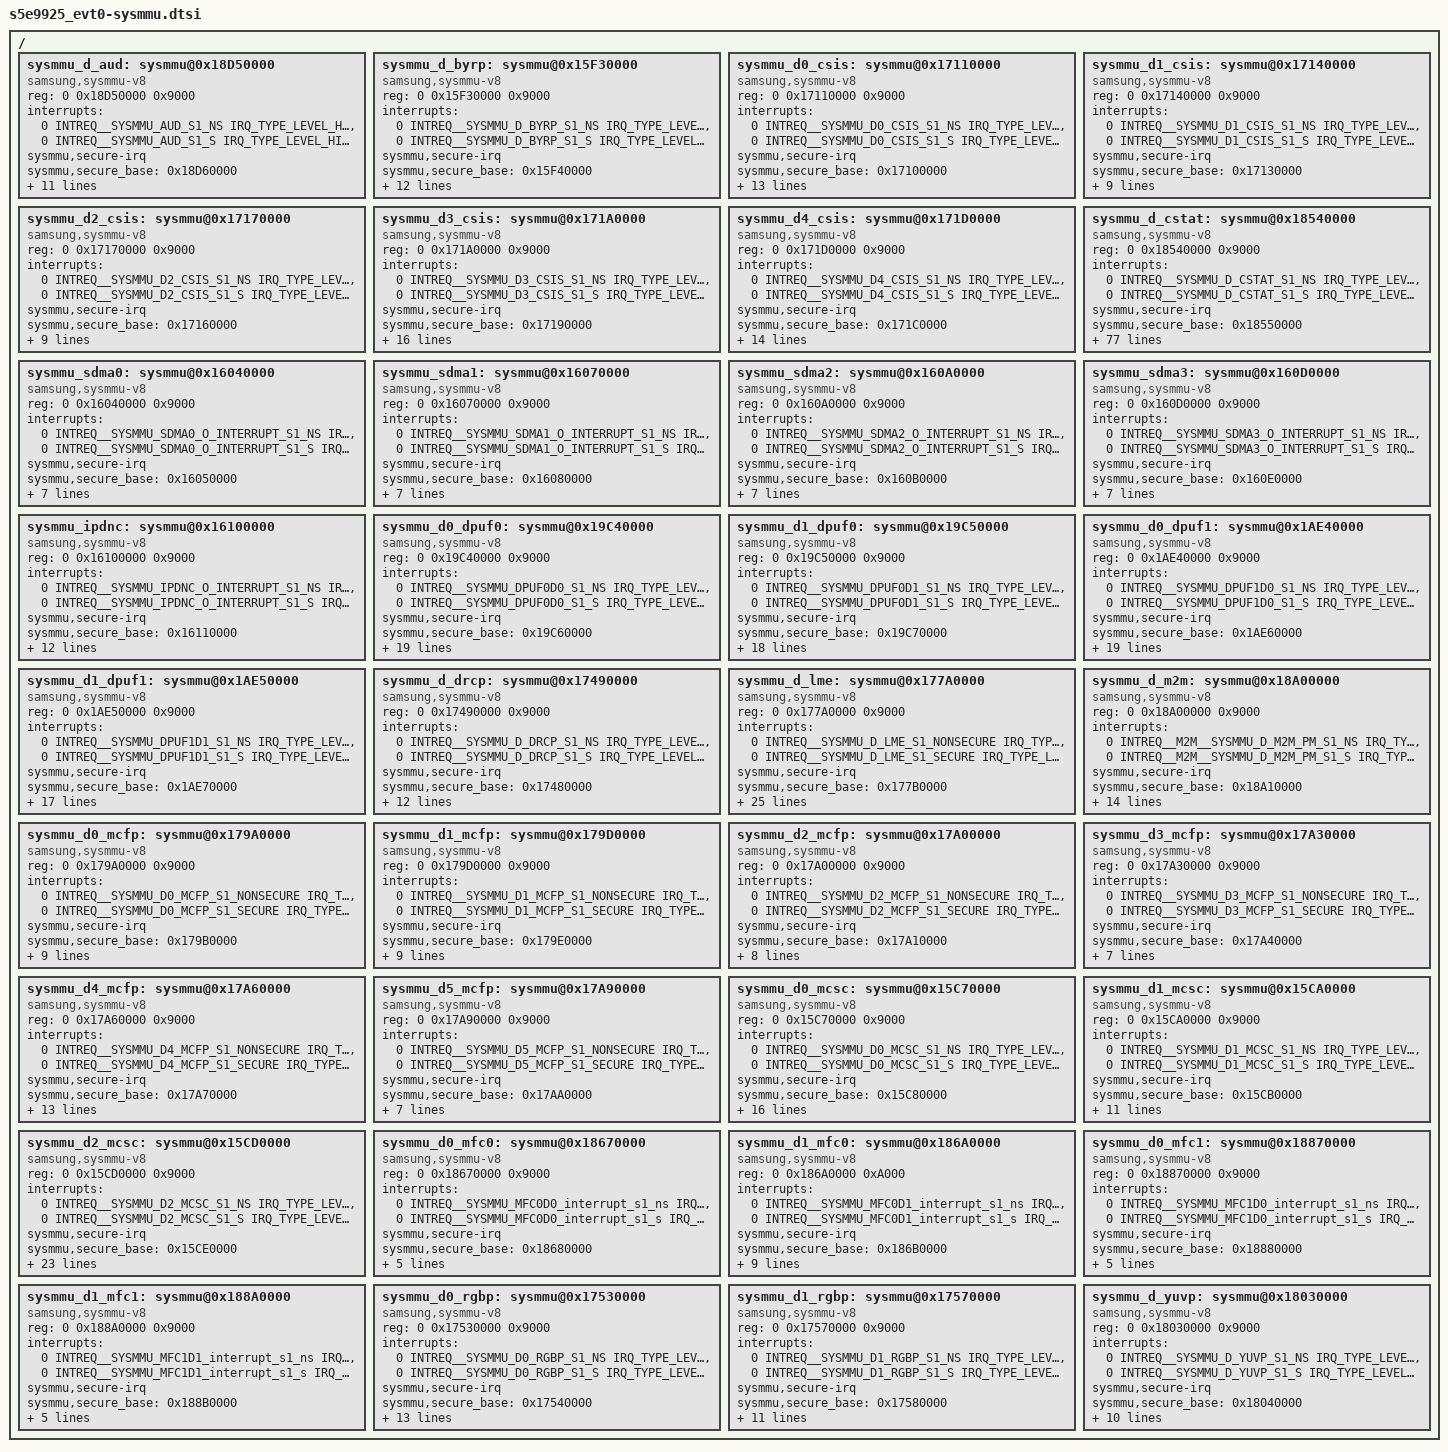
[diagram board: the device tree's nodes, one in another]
/*
 * SAMSUNG S5E9815 SoC device tree source
 *
 * Copyright (c) 2019 Samsung Electronics Co., Ltd.
 *		http://www.samsung.com
 *
 * SAMSUNG EXYNOS1000 SoC device nodes are listed in this file.
 * EXYNOS1000 based board files can include this file and provide
 * values for board specfic bindings.
 *
 * This program is free software; you can redistribute it and/or modify
 * it under the terms of the GNU General Public License version 2 as
 * published by the Free Software Foundation.
 */

#include <dt-bindings/interrupt-controller/arm-gic.h>
#include <dt-bindings/soc/samsung,sysmmu-v8.h>

/ {
	sysmmu_d_aud: sysmmu@0x18D50000 {
		compatible = "samsung,sysmmu-v8";
		reg = <0 0x18D50000 0x9000>;
		interrupts = <0 INTREQ__SYSMMU_AUD_S1_NS IRQ_TYPE_LEVEL_HIGH>,
				<0 INTREQ__SYSMMU_AUD_S1_S IRQ_TYPE_LEVEL_HIGH>;
		sysmmu,secure-irq;
		sysmmu,secure_base = <0x18D60000>;
		qos = <15>;
		#iommu-cells = <0>;
		sysmmu,default_tlb = <TLB_CFG(BL1, PREFETCH_NONE)>;
		sysmmu,tlb_property =
			<1 TLB_CFG(BL1, PREFETCH_NONE) DIR_RW SYSMMU_ID_MASK(0x3, 0xF)>,
			<2 TLB_CFG(BL1, PREFETCH_NONE) DIR_RW SYSMMU_ID_MASK(0x4, 0xF)>,
			<3 TLB_CFG(BL1, PREFETCH_NONE) DIR_RW SYSMMU_ID_MASK(0x5, 0xF)>,
			<4 TLB_CFG(BL1, PREFETCH_NONE) DIR_WRITE SYSMMU_ID_MASK(0x7, 0xF)>,
			<5 TLB_CFG(BL1, PREFETCH_NONE) DIR_WRITE SYSMMU_ID_MASK(0x8, 0xF)>;
		port-name = "ABOX (CA32_0), ABOX (UDMA), ...";
		power-domains = <&pd_aud>;
	};

	sysmmu_d_byrp: sysmmu@0x15F30000 {
		compatible = "samsung,sysmmu-v8";
		reg = <0 0x15F30000 0x9000>;
		interrupts = <0 INTREQ__SYSMMU_D_BYRP_S1_NS IRQ_TYPE_LEVEL_HIGH>,
				<0 INTREQ__SYSMMU_D_BYRP_S1_S IRQ_TYPE_LEVEL_HIGH>;
		sysmmu,secure-irq;
		sysmmu,secure_base = <0x15F40000>;
		qos = <15>;
		#iommu-cells = <0>;
		sysmmu,default_tlb = <TLB_CFG(BL1, PREFETCH_PREDICTION)>;
		sysmmu,tlb_property =
			<1 TLB_CFG(BL1, PREFETCH_PREDICTION) DIR_READ SYSMMU_ID_MASK(0x0, 0x7)>,
			<2 TLB_CFG(BL1, PREFETCH_PREDICTION) DIR_READ SYSMMU_ID_MASK(0x4, 0x7)>,
			<3 TLB_CFG(BL1, PREFETCH_PREDICTION) DIR_WRITE SYSMMU_ID_MASK(0x1, 0x7)>,
			<4 TLB_CFG(BL1, PREFETCH_NONE) DIR_READ SYSMMU_ID_MASK(0x1, 0x7)>,
			<5 TLB_CFG(BL1, PREFETCH_NONE) DIR_WRITE SYSMMU_ID_MASK(0x2, 0x7)>,
			<6 TLB_CFG(BL1, PREFETCH_NONE) DIR_WRITE SYSMMU_ID_MASK(0x3, 0x7)>;
		port-name = "BYRP(M0), BYRP(M1), BYRP(STR...";
		power-domains = <&pd_byrp>;
	};

	sysmmu_d0_csis: sysmmu@0x17110000 {
		compatible = "samsung,sysmmu-v8";
		reg = <0 0x17110000 0x9000>;
		interrupts = <0 INTREQ__SYSMMU_D0_CSIS_S1_NS IRQ_TYPE_LEVEL_HIGH>,
				<0 INTREQ__SYSMMU_D0_CSIS_S1_S IRQ_TYPE_LEVEL_HIGH>;
		sysmmu,secure-irq;
		sysmmu,secure_base = <0x17100000>;
		qos = <15>;
		#iommu-cells = <0>;
		sysmmu,default_tlb = <TLB_CFG(BL1, PREFETCH_PREDICTION)>;
		sysmmu,tlb_property =
			<1 TLB_CFG(BL1, PREFETCH_PREDICTION) DIR_WRITE SYSMMU_ID_MASK(0x1, 0x7)>,
			<2 TLB_CFG(BL1, PREFETCH_PREDICTION) DIR_WRITE SYSMMU_ID_MASK(0x2, 0x7)>,
			<3 TLB_CFG(BL1, PREFETCH_PREDICTION) DIR_WRITE SYSMMU_ID_MASK(0x3, 0x7)>,
			<4 TLB_CFG(BL1, PREFETCH_PREDICTION) DIR_WRITE SYSMMU_ID_MASK(0x4, 0x7)>,
			<5 TLB_CFG(BL1, PREFETCH_PREDICTION) DIR_WRITE SYSMMU_ID_MASK(0x5, 0x7)>,
			<6 TLB_CFG(BL1, PREFETCH_PREDICTION) DIR_WRITE SYSMMU_ID_MASK(0x6, 0x7)>,
			<7 TLB_CFG(BL1, PREFETCH_PREDICTION) DIR_WRITE SYSMMU_ID_MASK(0x7, 0x7)>;
		port-name = "CSISX7_V1.0 (CSIS DMA0)";
		power-domains = <&pd_csis>;
	};

	sysmmu_d1_csis: sysmmu@0x17140000 {
		compatible = "samsung,sysmmu-v8";
		reg = <0 0x17140000 0x9000>;
		interrupts = <0 INTREQ__SYSMMU_D1_CSIS_S1_NS IRQ_TYPE_LEVEL_HIGH>,
				<0 INTREQ__SYSMMU_D1_CSIS_S1_S IRQ_TYPE_LEVEL_HIGH>;
		sysmmu,secure-irq;
		sysmmu,secure_base = <0x17130000>;
		qos = <15>;
		#iommu-cells = <0>;
		sysmmu,default_tlb = <TLB_CFG(BL1, PREFETCH_PREDICTION)>;
		sysmmu,tlb_property =
			<1 TLB_CFG(BL1, PREFETCH_PREDICTION) DIR_WRITE SYSMMU_ID_MASK(0x2, 0x7)>,
			<2 TLB_CFG(BL1, PREFETCH_PREDICTION) DIR_WRITE SYSMMU_ID_MASK(0x4, 0x7)>,
			<3 TLB_CFG(BL1, PREFETCH_PREDICTION) DIR_WRITE SYSMMU_ID_MASK(0x6, 0x7)>;
		port-name = "CSISX7_V1.0 (CSIS DMA1)";
		power-domains = <&pd_csis>;
	};

	sysmmu_d2_csis: sysmmu@0x17170000 {
		compatible = "samsung,sysmmu-v8";
		reg = <0 0x17170000 0x9000>;
		interrupts = <0 INTREQ__SYSMMU_D2_CSIS_S1_NS IRQ_TYPE_LEVEL_HIGH>,
				<0 INTREQ__SYSMMU_D2_CSIS_S1_S IRQ_TYPE_LEVEL_HIGH>;
		sysmmu,secure-irq;
		sysmmu,secure_base = <0x17160000>;
		qos = <15>;
		#iommu-cells = <0>;
		sysmmu,default_tlb = <TLB_CFG(BL1, PREFETCH_PREDICTION)>;
		sysmmu,tlb_property =
			<1 TLB_CFG(BL1, PREFETCH_PREDICTION) DIR_WRITE SYSMMU_ID_MASK(0x2, 0x7)>,
			<2 TLB_CFG(BL1, PREFETCH_PREDICTION) DIR_WRITE SYSMMU_ID_MASK(0x4, 0x7)>,
			<3 TLB_CFG(BL1, PREFETCH_PREDICTION) DIR_WRITE SYSMMU_ID_MASK(0x6, 0x7)>;
		port-name = "CSISX7_V1.0 (CSIS DMA2)";
		power-domains = <&pd_csis>;
	};

	sysmmu_d3_csis: sysmmu@0x171A0000 {
		compatible = "samsung,sysmmu-v8";
		reg = <0 0x171A0000 0x9000>;
		interrupts = <0 INTREQ__SYSMMU_D3_CSIS_S1_NS IRQ_TYPE_LEVEL_HIGH>,
				<0 INTREQ__SYSMMU_D3_CSIS_S1_S IRQ_TYPE_LEVEL_HIGH>;
		sysmmu,secure-irq;
		sysmmu,secure_base = <0x17190000>;
		qos = <15>;
		#iommu-cells = <0>;
		sysmmu,default_tlb = <TLB_CFG(BL1, PREFETCH_PREDICTION)>;
		sysmmu,tlb_property =
			<1 TLB_CFG(BL1, PREFETCH_PREDICTION) DIR_WRITE SYSMMU_ID_MASK(0x10, 0x3F)>,
			<2 TLB_CFG(BL1, PREFETCH_PREDICTION) DIR_WRITE SYSMMU_ID_MASK(0x20, 0x3F)>,
			<3 TLB_CFG(BL1, PREFETCH_PREDICTION) DIR_WRITE SYSMMU_ID_MASK(0x30, 0x3F)>,
			<9 TLB_CFG(BL1, PREFETCH_NONE) DIR_WRITE SYSMMU_ID_MASK(0x3, 0x1F)>,
			<10 TLB_CFG(BL1, PREFETCH_NONE) DIR_WRITE SYSMMU_ID_MASK(0x4, 0x1F)>,
			<4 TLB_CFG(BL1, PREFETCH_PREDICTION) DIR_WRITE SYSMMU_ID_MASK(0x1, 0x1F)>,
			<5 TLB_CFG(BL1, PREFETCH_PREDICTION) DIR_READ SYSMMU_ID_MASK(0x1, 0x1F)>,
			<6 TLB_CFG(BL1, PREFETCH_PREDICTION) DIR_READ SYSMMU_ID_MASK(0x9, 0x1F)>,
			<7 TLB_CFG(BL1, PREFETCH_PREDICTION) DIR_WRITE SYSMMU_ID_MASK(0x2, 0x1F)>,
			<8 TLB_CFG(BL1, PREFETCH_PREDICTION) DIR_READ SYSMMU_ID_MASK(0x2, 0x1F)>;
		port-name = "CSISX7_V1.0 (CSIS DMA3), CSI...";
		power-domains = <&pd_csis>;
	};

	sysmmu_d4_csis: sysmmu@0x171D0000 {
		compatible = "samsung,sysmmu-v8";
		reg = <0 0x171D0000 0x9000>;
		interrupts = <0 INTREQ__SYSMMU_D4_CSIS_S1_NS IRQ_TYPE_LEVEL_HIGH>,
				<0 INTREQ__SYSMMU_D4_CSIS_S1_S IRQ_TYPE_LEVEL_HIGH>;
		sysmmu,secure-irq;
		sysmmu,secure_base = <0x171C0000>;
		qos = <15>;
		#iommu-cells = <0>;
		sysmmu,default_tlb = <TLB_CFG(BL1, PREFETCH_PREDICTION)>;
		sysmmu,tlb_property =
			<1 TLB_CFG(BL1, PREFETCH_PREDICTION) DIR_WRITE SYSMMU_ID_MASK(0x8, 0x1F)>,
			<2 TLB_CFG(BL1, PREFETCH_PREDICTION) DIR_WRITE SYSMMU_ID_MASK(0x10, 0x1F)>,
			<3 TLB_CFG(BL1, PREFETCH_PREDICTION) DIR_WRITE SYSMMU_ID_MASK(0x18, 0x1F)>,
			<4 TLB_CFG(BL1, PREFETCH_PREDICTION) DIR_WRITE SYSMMU_ID_MASK(0x1, 0x7)>,
			<5 TLB_CFG(BL1, PREFETCH_PREDICTION) DIR_READ SYSMMU_ID_MASK(0x1, 0x7)>,
			<6 TLB_CFG(BL1, PREFETCH_PREDICTION) DIR_WRITE SYSMMU_ID_MASK(0x2, 0x7)>,
			<7 TLB_CFG(BL1, PREFETCH_PREDICTION) DIR_READ SYSMMU_ID_MASK(0x2, 0x7)>,
			<8 TLB_CFG(BL1, PREFETCH_NONE) DIR_WRITE SYSMMU_ID_MASK(0x3, 0x7)>;
		port-name = "CSISX7_V1.0 (CSIS DMA4), PDP...";
		power-domains = <&pd_csis>;
	};

	sysmmu_d_cstat: sysmmu@0x18540000 {
		compatible = "samsung,sysmmu-v8";
		reg = <0 0x18540000 0x9000>;
		interrupts = <0 INTREQ__SYSMMU_D_CSTAT_S1_NS IRQ_TYPE_LEVEL_HIGH>,
				<0 INTREQ__SYSMMU_D_CSTAT_S1_S IRQ_TYPE_LEVEL_HIGH>;
		sysmmu,secure-irq;
		sysmmu,secure_base = <0x18550000>;
		qos = <15>;
		#iommu-cells = <0>;
		sysmmu,default_tlb = <TLB_CFG(BL1, PREFETCH_PREDICTION)>;
		sysmmu,tlb_property =
			<1 TLB_CFG(BL1, PREFETCH_PREDICTION) DIR_READ SYSMMU_ID_MASK(0x0, 0x3FF)>,
			<2 TLB_CFG(BL1, PREFETCH_PREDICTION) DIR_WRITE SYSMMU_ID_MASK(0x1, 0x3FF)>,
			<3 TLB_CFG(BL1, PREFETCH_PREDICTION) DIR_READ SYSMMU_ID_MASK(0x1, 0x3FF)>,
			<4 TLB_CFG(BL1, PREFETCH_PREDICTION) DIR_WRITE SYSMMU_ID_MASK(0x2, 0x3FF)>,
			<5 TLB_CFG(BL1, PREFETCH_PREDICTION) DIR_READ SYSMMU_ID_MASK(0x2, 0x3FF)>,
			<6 TLB_CFG(BL1, PREFETCH_PREDICTION) DIR_WRITE SYSMMU_ID_MASK(0x3, 0x3FF)>,
			<7 TLB_CFG(BL1, PREFETCH_PREDICTION) DIR_READ SYSMMU_ID_MASK(0x3, 0x3FF)>,
			<8 TLB_CFG(BL1, PREFETCH_PREDICTION) DIR_WRITE SYSMMU_ID_MASK(0x4, 0x3FF)>,
			<64 TLB_CFG(BL1, PREFETCH_NONE) DIR_READ SYSMMU_ID_MASK(0x4, 0x3FF)>,
			<9 TLB_CFG(BL1, PREFETCH_PREDICTION) DIR_WRITE SYSMMU_ID_MASK(0x5, 0x3FF)>,
			<65 TLB_CFG(BL1, PREFETCH_NONE) DIR_READ SYSMMU_ID_MASK(0x5, 0x3FF)>,
			<10 TLB_CFG(BL1, PREFETCH_PREDICTION) DIR_WRITE SYSMMU_ID_MASK(0x6, 0x3FF)>,
			<66 TLB_CFG(BL1, PREFETCH_NONE) DIR_READ SYSMMU_ID_MASK(0x6, 0x3FF)>,
			<11 TLB_CFG(BL1, PREFETCH_PREDICTION) DIR_WRITE SYSMMU_ID_MASK(0x7, 0x3FF)>,
			<67 TLB_CFG(BL1, PREFETCH_NONE) DIR_READ SYSMMU_ID_MASK(0x7, 0x3FF)>,
			<12 TLB_CFG(BL1, PREFETCH_PREDICTION) DIR_WRITE SYSMMU_ID_MASK(0x8, 0x3FF)>,
			<13 TLB_CFG(BL1, PREFETCH_PREDICTION) DIR_WRITE SYSMMU_ID_MASK(0x108, 0x3FF)>,
			<14 TLB_CFG(BL1, PREFETCH_PREDICTION) DIR_WRITE SYSMMU_ID_MASK(0x208, 0x3FF)>,
			<15 TLB_CFG(BL1, PREFETCH_PREDICTION) DIR_WRITE SYSMMU_ID_MASK(0x308, 0x3FF)>,
			<16 TLB_CFG(BL1, PREFETCH_PREDICTION) DIR_WRITE SYSMMU_ID_MASK(0x9, 0x3FF)>,
			<17 TLB_CFG(BL1, PREFETCH_PREDICTION) DIR_WRITE SYSMMU_ID_MASK(0x109, 0x3FF)>,
			<18 TLB_CFG(BL1, PREFETCH_PREDICTION) DIR_WRITE SYSMMU_ID_MASK(0x209, 0x3FF)>,
			<19 TLB_CFG(BL1, PREFETCH_PREDICTION) DIR_WRITE SYSMMU_ID_MASK(0x309, 0x3FF)>,
			<20 TLB_CFG(BL1, PREFETCH_PREDICTION) DIR_WRITE SYSMMU_ID_MASK(0xA, 0x3FF)>,
			<21 TLB_CFG(BL1, PREFETCH_PREDICTION) DIR_WRITE SYSMMU_ID_MASK(0x10A, 0x3FF)>,
			<22 TLB_CFG(BL1, PREFETCH_PREDICTION) DIR_WRITE SYSMMU_ID_MASK(0x20A, 0x3FF)>,
			<23 TLB_CFG(BL1, PREFETCH_PREDICTION) DIR_WRITE SYSMMU_ID_MASK(0x30A, 0x3FF)>,
			<24 TLB_CFG(BL1, PREFETCH_PREDICTION) DIR_WRITE SYSMMU_ID_MASK(0xB, 0x3FF)>,
			<25 TLB_CFG(BL1, PREFETCH_PREDICTION) DIR_WRITE SYSMMU_ID_MASK(0x10B, 0x3FF)>,
			<26 TLB_CFG(BL1, PREFETCH_PREDICTION) DIR_WRITE SYSMMU_ID_MASK(0x20B, 0x3FF)>,
			<27 TLB_CFG(BL1, PREFETCH_PREDICTION) DIR_WRITE SYSMMU_ID_MASK(0x30B, 0x3FF)>,
			<28 TLB_CFG(BL1, PREFETCH_PREDICTION) DIR_WRITE SYSMMU_ID_MASK(0xC, 0x3FF)>,
			<29 TLB_CFG(BL1, PREFETCH_PREDICTION) DIR_WRITE SYSMMU_ID_MASK(0x10C, 0x3FF)>,
			<30 TLB_CFG(BL1, PREFETCH_PREDICTION) DIR_WRITE SYSMMU_ID_MASK(0x20C, 0x3FF)>,
			<31 TLB_CFG(BL1, PREFETCH_PREDICTION) DIR_WRITE SYSMMU_ID_MASK(0x30C, 0x3FF)>,
			<32 TLB_CFG(BL1, PREFETCH_PREDICTION) DIR_WRITE SYSMMU_ID_MASK(0xD, 0x3FF)>,
			<33 TLB_CFG(BL1, PREFETCH_PREDICTION) DIR_WRITE SYSMMU_ID_MASK(0x10D, 0x3FF)>,
			<34 TLB_CFG(BL1, PREFETCH_PREDICTION) DIR_WRITE SYSMMU_ID_MASK(0x20D, 0x3FF)>,
			<35 TLB_CFG(BL1, PREFETCH_PREDICTION) DIR_WRITE SYSMMU_ID_MASK(0x30D, 0x3FF)>,
			<36 TLB_CFG(BL1, PREFETCH_PREDICTION) DIR_WRITE SYSMMU_ID_MASK(0xE, 0x3FF)>,
			<37 TLB_CFG(BL1, PREFETCH_PREDICTION) DIR_WRITE SYSMMU_ID_MASK(0x10E, 0x3FF)>,
			<38 TLB_CFG(BL1, PREFETCH_PREDICTION) DIR_WRITE SYSMMU_ID_MASK(0x20E, 0x3FF)>,
			<39 TLB_CFG(BL1, PREFETCH_PREDICTION) DIR_WRITE SYSMMU_ID_MASK(0x30E, 0x3FF)>,
			<40 TLB_CFG(BL1, PREFETCH_PREDICTION) DIR_WRITE SYSMMU_ID_MASK(0xF, 0x3FF)>,
			<41 TLB_CFG(BL1, PREFETCH_PREDICTION) DIR_WRITE SYSMMU_ID_MASK(0x4F, 0x3FF)>,
			<42 TLB_CFG(BL1, PREFETCH_PREDICTION) DIR_WRITE SYSMMU_ID_MASK(0x8F, 0x3FF)>,
			<43 TLB_CFG(BL1, PREFETCH_PREDICTION) DIR_WRITE SYSMMU_ID_MASK(0x10F, 0x3FF)>,
			<44 TLB_CFG(BL1, PREFETCH_PREDICTION) DIR_WRITE SYSMMU_ID_MASK(0x14F, 0x3FF)>,
			<45 TLB_CFG(BL1, PREFETCH_PREDICTION) DIR_WRITE SYSMMU_ID_MASK(0x18F, 0x3FF)>,
			<46 TLB_CFG(BL1, PREFETCH_PREDICTION) DIR_WRITE SYSMMU_ID_MASK(0x20F, 0x3FF)>,
			<47 TLB_CFG(BL1, PREFETCH_PREDICTION) DIR_WRITE SYSMMU_ID_MASK(0x24F, 0x3FF)>,
			<48 TLB_CFG(BL1, PREFETCH_PREDICTION) DIR_WRITE SYSMMU_ID_MASK(0x28F, 0x3FF)>,
			<49 TLB_CFG(BL1, PREFETCH_PREDICTION) DIR_WRITE SYSMMU_ID_MASK(0x30F, 0x3FF)>,
			<50 TLB_CFG(BL1, PREFETCH_PREDICTION) DIR_WRITE SYSMMU_ID_MASK(0x34F, 0x3FF)>,
			<51 TLB_CFG(BL1, PREFETCH_PREDICTION) DIR_WRITE SYSMMU_ID_MASK(0x38F, 0x3FF)>,
			<52 TLB_CFG(BL1, PREFETCH_PREDICTION) DIR_WRITE SYSMMU_ID_MASK(0x10, 0x3FF)>,
			<53 TLB_CFG(BL1, PREFETCH_PREDICTION) DIR_WRITE SYSMMU_ID_MASK(0x50, 0x3FF)>,
			<54 TLB_CFG(BL1, PREFETCH_PREDICTION) DIR_WRITE SYSMMU_ID_MASK(0x90, 0x3FF)>,
			<55 TLB_CFG(BL1, PREFETCH_PREDICTION) DIR_WRITE SYSMMU_ID_MASK(0x110, 0x3FF)>,
			<56 TLB_CFG(BL1, PREFETCH_PREDICTION) DIR_WRITE SYSMMU_ID_MASK(0x150, 0x3FF)>,
			<57 TLB_CFG(BL1, PREFETCH_PREDICTION) DIR_WRITE SYSMMU_ID_MASK(0x190, 0x3FF)>,
			<58 TLB_CFG(BL1, PREFETCH_PREDICTION) DIR_WRITE SYSMMU_ID_MASK(0x210, 0x3FF)>,
			<59 TLB_CFG(BL1, PREFETCH_PREDICTION) DIR_WRITE SYSMMU_ID_MASK(0x250, 0x3FF)>,
			<60 TLB_CFG(BL1, PREFETCH_PREDICTION) DIR_WRITE SYSMMU_ID_MASK(0x290, 0x3FF)>,
			<61 TLB_CFG(BL1, PREFETCH_PREDICTION) DIR_WRITE SYSMMU_ID_MASK(0x310, 0x3FF)>,
			<62 TLB_CFG(BL1, PREFETCH_PREDICTION) DIR_WRITE SYSMMU_ID_MASK(0x350, 0x3FF)>,
			<63 TLB_CFG(BL1, PREFETCH_PREDICTION) DIR_WRITE SYSMMU_ID_MASK(0x390, 0x3FF)>,
			<68 TLB_CFG(BL1, PREFETCH_NONE) DIR_WRITE SYSMMU_ID_MASK(0x11, 0x3F)>,
			<69 TLB_CFG(BL1, PREFETCH_NONE) DIR_WRITE SYSMMU_ID_MASK(0x12, 0x3F)>,
			<70 TLB_CFG(BL1, PREFETCH_NONE) DIR_WRITE SYSMMU_ID_MASK(0x13, 0x3F)>,
			<71 TLB_CFG(BL1, PREFETCH_NONE) DIR_WRITE SYSMMU_ID_MASK(0x14, 0x3F)>;
		port-name = "CSTAT_RD0_HIST0, CSTAT_RD1_H...";
		power-domains = <&pd_cstat>;
	};

	sysmmu_sdma0: sysmmu@0x16040000 {
		compatible = "samsung,sysmmu-v8";
		reg = <0 0x16040000 0x9000>;
		interrupts = <0 INTREQ__SYSMMU_SDMA0_O_INTERRUPT_S1_NS IRQ_TYPE_LEVEL_HIGH>,
				<0 INTREQ__SYSMMU_SDMA0_O_INTERRUPT_S1_S IRQ_TYPE_LEVEL_HIGH>;
		sysmmu,secure-irq;
		sysmmu,secure_base = <0x16050000>;
		qos = <15>;
		#iommu-cells = <0>;
		sysmmu,default_tlb = <TLB_CFG(BL1, PREFETCH_NONE)>;
		sysmmu,tlb_property =
			<1 TLB_CFG(BL8, PREFETCH_NONE) DIR_RW SYSMMU_ID_MASK(0x0, 0x60)>;
		port-name = "IP_SDMA (BUSD0)";
		power-domains = <&pd_dnc>;
	};

	sysmmu_sdma1: sysmmu@0x16070000 {
		compatible = "samsung,sysmmu-v8";
		reg = <0 0x16070000 0x9000>;
		interrupts = <0 INTREQ__SYSMMU_SDMA1_O_INTERRUPT_S1_NS IRQ_TYPE_LEVEL_HIGH>,
				<0 INTREQ__SYSMMU_SDMA1_O_INTERRUPT_S1_S IRQ_TYPE_LEVEL_HIGH>;
		sysmmu,secure-irq;
		sysmmu,secure_base = <0x16080000>;
		qos = <15>;
		#iommu-cells = <0>;
		sysmmu,default_tlb = <TLB_CFG(BL1, PREFETCH_NONE)>;
		sysmmu,tlb_property =
			<1 TLB_CFG(BL8, PREFETCH_NONE) DIR_RW SYSMMU_ID_MASK(0x0, 0x60)>;
		port-name = "IP_SDMA (BUSD0)";
		power-domains = <&pd_dnc>;
	};

	sysmmu_sdma2: sysmmu@0x160A0000 {
		compatible = "samsung,sysmmu-v8";
		reg = <0 0x160A0000 0x9000>;
		interrupts = <0 INTREQ__SYSMMU_SDMA2_O_INTERRUPT_S1_NS IRQ_TYPE_LEVEL_HIGH>,
				<0 INTREQ__SYSMMU_SDMA2_O_INTERRUPT_S1_S IRQ_TYPE_LEVEL_HIGH>;
		sysmmu,secure-irq;
		sysmmu,secure_base = <0x160B0000>;
		qos = <15>;
		#iommu-cells = <0>;
		sysmmu,default_tlb = <TLB_CFG(BL1, PREFETCH_NONE)>;
		sysmmu,tlb_property =
			<1 TLB_CFG(BL8, PREFETCH_NONE) DIR_RW SYSMMU_ID_MASK(0x0, 0x60)>;
		port-name = "IP_SDMA (BUSD0)";
		power-domains = <&pd_dnc>;
	};

	sysmmu_sdma3: sysmmu@0x160D0000 {
		compatible = "samsung,sysmmu-v8";
		reg = <0 0x160D0000 0x9000>;
		interrupts = <0 INTREQ__SYSMMU_SDMA3_O_INTERRUPT_S1_NS IRQ_TYPE_LEVEL_HIGH>,
				<0 INTREQ__SYSMMU_SDMA3_O_INTERRUPT_S1_S IRQ_TYPE_LEVEL_HIGH>;
		sysmmu,secure-irq;
		sysmmu,secure_base = <0x160E0000>;
		qos = <15>;
		#iommu-cells = <0>;
		sysmmu,default_tlb = <TLB_CFG(BL1, PREFETCH_NONE)>;
		sysmmu,tlb_property =
			<1 TLB_CFG(BL8, PREFETCH_NONE) DIR_RW SYSMMU_ID_MASK(0x0, 0x60)>;
		port-name = "IP_SDMA (BUSD0)";
		power-domains = <&pd_dnc>;
	};

	sysmmu_ipdnc: sysmmu@0x16100000 {
		compatible = "samsung,sysmmu-v8";
		reg = <0 0x16100000 0x9000>;
		interrupts = <0 INTREQ__SYSMMU_IPDNC_O_INTERRUPT_S1_NS IRQ_TYPE_LEVEL_HIGH>,
				<0 INTREQ__SYSMMU_IPDNC_O_INTERRUPT_S1_S IRQ_TYPE_LEVEL_HIGH>;
		sysmmu,secure-irq;
		sysmmu,secure_base = <0x16110000>;
		qos = <15>;
		#iommu-cells = <0>;
		sysmmu,default_tlb = <TLB_CFG(BL1, PREFETCH_NONE)>;
		sysmmu,tlb_property =
			<1 TLB_CFG(BL1, PREFETCH_NONE) DIR_READ SYSMMU_ID_MASK(0x2, 0xf)>,
			<2 TLB_CFG(BL1, PREFETCH_NONE) DIR_READ SYSMMU_ID_MASK(0x3, 0xf)>,
			<4 TLB_CFG(BL1, PREFETCH_PREDICTION) DIR_READ SYSMMU_ID_MASK(0x9, 0xf)>,
			<5 TLB_CFG(BL1, PREFETCH_PREDICTION) DIR_READ SYSMMU_ID_MASK(0x4, 0x7)>,
			<6 TLB_CFG(BL1, PREFETCH_NONE) DIR_RW SYSMMU_ID_MASK(0x0, 0x7)>,
			<7 TLB_CFG(BL1, PREFETCH_NONE) DIR_WRITE SYSMMU_ID_MASK(0x5, 0x7)>;
		port-name = "IP_DNC (DRAM)";
		power-domains = <&pd_dnc>;
	};

	sysmmu_d0_dpuf0: sysmmu@0x19C40000 {
		compatible = "samsung,sysmmu-v8";
		reg = <0 0x19C40000 0x9000>;
		interrupts = <0 INTREQ__SYSMMU_DPUF0D0_S1_NS IRQ_TYPE_LEVEL_HIGH>,
				<0 INTREQ__SYSMMU_DPUF0D0_S1_S IRQ_TYPE_LEVEL_HIGH>;
		sysmmu,secure-irq;
		sysmmu,secure_base = <0x19C60000>;
		qos = <15>;
		#iommu-cells = <0>;
		sysmmu,default_tlb = <TLB_CFG(BL32, PREFETCH_PREDICTION)>;
		sysmmu,tlb_property =
			<2 TLB_CFG(BL16, PREFETCH_PREDICTION) DIR_READ SYSMMU_ID_MASK(0x0, 0x1F)>,
			<1 TLB_CFG(BL32, PREFETCH_PREDICTION) DIR_READ SYSMMU_ID_MASK(0x5, 0x1F)>,
			<4 TLB_CFG(BL2, PREFETCH_PREDICTION) DIR_READ SYSMMU_ID_MASK(0x6, 0x1F)>,
			<7 TLB_CFG(BL1, PREFETCH_PREDICTION) DIR_READ SYSMMU_ID_MASK(0x7, 0x1F)>,
			<3 TLB_CFG(BL16, PREFETCH_PREDICTION) DIR_READ SYSMMU_ID_MASK(0x8, 0x1F)>,
			<5 TLB_CFG(BL2, PREFETCH_PREDICTION) DIR_READ SYSMMU_ID_MASK(0xC, 0x1F)>,
			<6 TLB_CFG(BL2, PREFETCH_PREDICTION) DIR_READ SYSMMU_ID_MASK(0xD, 0x1F)>,
			<8 TLB_CFG(BL1, PREFETCH_PREDICTION) DIR_READ SYSMMU_ID_MASK(0xE, 0x1F)>,
			<9 TLB_CFG(BL1, PREFETCH_PREDICTION) DIR_READ SYSMMU_ID_MASK(0xF, 0x1F)>,
			<10 TLB_CFG(BL1, PREFETCH_PREDICTION) DIR_READ SYSMMU_ID_MASK(0x10, 0x1F)>,
			<11 TLB_CFG(BL1, PREFETCH_PREDICTION) DIR_READ SYSMMU_ID_MASK(0x14, 0x1F)>,
			<12 TLB_CFG(BL1, PREFETCH_NONE) DIR_WRITE SYSMMU_ID_MASK(0x10, 0x1F)>,
			<13 TLB_CFG(BL1, PREFETCH_NONE) DIR_WRITE SYSMMU_ID_MASK(0x14, 0x1F)>;
		port-name = "DPUF0 D0";
		power-domains = <&pd_dpuf0>;
	};

	sysmmu_d1_dpuf0: sysmmu@0x19C50000 {
		compatible = "samsung,sysmmu-v8";
		reg = <0 0x19C50000 0x9000>;
		interrupts = <0 INTREQ__SYSMMU_DPUF0D1_S1_NS IRQ_TYPE_LEVEL_HIGH>,
				<0 INTREQ__SYSMMU_DPUF0D1_S1_S IRQ_TYPE_LEVEL_HIGH>;
		sysmmu,secure-irq;
		sysmmu,secure_base = <0x19C70000>;
		qos = <15>;
		#iommu-cells = <0>;
		sysmmu,default_tlb = <TLB_CFG(BL16, PREFETCH_PREDICTION)>;
		sysmmu,tlb_property =
			<1 TLB_CFG(BL16, PREFETCH_PREDICTION) DIR_READ SYSMMU_ID_MASK(0x4, 0x1F)>,
			<2 TLB_CFG(BL2, PREFETCH_PREDICTION) DIR_READ SYSMMU_ID_MASK(0x5, 0x1F)>,
			<6 TLB_CFG(BL1, PREFETCH_PREDICTION) DIR_READ SYSMMU_ID_MASK(0x6, 0x1F)>,
			<7 TLB_CFG(BL1, PREFETCH_PREDICTION) DIR_READ SYSMMU_ID_MASK(0x7, 0x1F)>,
			<3 TLB_CFG(BL2, PREFETCH_PREDICTION) DIR_READ SYSMMU_ID_MASK(0x8, 0x1F)>,
			<4 TLB_CFG(BL2, PREFETCH_PREDICTION) DIR_READ SYSMMU_ID_MASK(0xC, 0x1F)>,
			<5 TLB_CFG(BL2, PREFETCH_PREDICTION) DIR_READ SYSMMU_ID_MASK(0xD, 0x1F)>,
			<8 TLB_CFG(BL1, PREFETCH_PREDICTION) DIR_READ SYSMMU_ID_MASK(0xE, 0x1F)>,
			<9 TLB_CFG(BL1, PREFETCH_PREDICTION) DIR_READ SYSMMU_ID_MASK(0xF, 0x1F)>,
			<10 TLB_CFG(BL1, PREFETCH_PREDICTION) DIR_READ SYSMMU_ID_MASK(0x11, 0x1F)>,
			<11 TLB_CFG(BL1, PREFETCH_PREDICTION) DIR_WRITE SYSMMU_ID_MASK(0x0, 0x1F)>,
			<12 TLB_CFG(BL1, PREFETCH_PREDICTION) DIR_WRITE SYSMMU_ID_MASK(0x1, 0x1F)>;
		port-name = "DPUF0 D1";
		power-domains = <&pd_dpuf0>;
	};

	sysmmu_d0_dpuf1: sysmmu@0x1AE40000 {
		compatible = "samsung,sysmmu-v8";
		reg = <0 0x1AE40000 0x9000>;
		interrupts = <0 INTREQ__SYSMMU_DPUF1D0_S1_NS IRQ_TYPE_LEVEL_HIGH>,
				<0 INTREQ__SYSMMU_DPUF1D0_S1_S IRQ_TYPE_LEVEL_HIGH>;
		sysmmu,secure-irq;
		sysmmu,secure_base = <0x1AE60000>;
		qos = <15>;
		#iommu-cells = <0>;
		sysmmu,default_tlb = <TLB_CFG(BL32, PREFETCH_PREDICTION)>;
		sysmmu,tlb_property =
			<2 TLB_CFG(BL16, PREFETCH_PREDICTION) DIR_READ SYSMMU_ID_MASK(0x0, 0x1F)>,
			<1 TLB_CFG(BL32, PREFETCH_PREDICTION) DIR_READ SYSMMU_ID_MASK(0x5, 0x1F)>,
			<4 TLB_CFG(BL2, PREFETCH_PREDICTION) DIR_READ SYSMMU_ID_MASK(0x6, 0x1F)>,
			<7 TLB_CFG(BL1, PREFETCH_PREDICTION) DIR_READ SYSMMU_ID_MASK(0x7, 0x1F)>,
			<3 TLB_CFG(BL16, PREFETCH_PREDICTION) DIR_READ SYSMMU_ID_MASK(0x8, 0x1F)>,
			<5 TLB_CFG(BL2, PREFETCH_PREDICTION) DIR_READ SYSMMU_ID_MASK(0xC, 0x1F)>,
			<6 TLB_CFG(BL2, PREFETCH_PREDICTION) DIR_READ SYSMMU_ID_MASK(0xD, 0x1F)>,
			<8 TLB_CFG(BL1, PREFETCH_PREDICTION) DIR_READ SYSMMU_ID_MASK(0xE, 0x1F)>,
			<9 TLB_CFG(BL1, PREFETCH_PREDICTION) DIR_READ SYSMMU_ID_MASK(0xF, 0x1F)>,
			<10 TLB_CFG(BL1, PREFETCH_PREDICTION) DIR_READ SYSMMU_ID_MASK(0x10, 0x1F)>,
			<11 TLB_CFG(BL1, PREFETCH_PREDICTION) DIR_READ SYSMMU_ID_MASK(0x14, 0x1F)>,
			<12 TLB_CFG(BL1, PREFETCH_NONE) DIR_WRITE SYSMMU_ID_MASK(0x10, 0x1F)>,
			<13 TLB_CFG(BL1, PREFETCH_NONE) DIR_WRITE SYSMMU_ID_MASK(0x14, 0x1F)>;
		port-name = "DPUF1 D0";
		power-domains = <&pd_dpuf1>;
	};

	sysmmu_d1_dpuf1: sysmmu@0x1AE50000 {
		compatible = "samsung,sysmmu-v8";
		reg = <0 0x1AE50000 0x9000>;
		interrupts = <0 INTREQ__SYSMMU_DPUF1D1_S1_NS IRQ_TYPE_LEVEL_HIGH>,
				<0 INTREQ__SYSMMU_DPUF1D1_S1_S IRQ_TYPE_LEVEL_HIGH>;
		sysmmu,secure-irq;
		sysmmu,secure_base = <0x1AE70000>;
		qos = <15>;
		#iommu-cells = <0>;
		sysmmu,default_tlb = <TLB_CFG(BL16, PREFETCH_PREDICTION)>;
		sysmmu,tlb_property =
			<1 TLB_CFG(BL16, PREFETCH_PREDICTION) DIR_READ SYSMMU_ID_MASK(0x4, 0x1F)>,
			<2 TLB_CFG(BL2, PREFETCH_PREDICTION) DIR_READ SYSMMU_ID_MASK(0x5, 0x1F)>,
			<6 TLB_CFG(BL1, PREFETCH_PREDICTION) DIR_READ SYSMMU_ID_MASK(0x6, 0x1F)>,
			<7 TLB_CFG(BL1, PREFETCH_PREDICTION) DIR_READ SYSMMU_ID_MASK(0x7, 0x1F)>,
			<3 TLB_CFG(BL2, PREFETCH_PREDICTION) DIR_READ SYSMMU_ID_MASK(0x8, 0x1F)>,
			<4 TLB_CFG(BL2, PREFETCH_PREDICTION) DIR_READ SYSMMU_ID_MASK(0xC, 0x1F)>,
			<5 TLB_CFG(BL2, PREFETCH_PREDICTION) DIR_READ SYSMMU_ID_MASK(0xD, 0x1F)>,
			<8 TLB_CFG(BL1, PREFETCH_PREDICTION) DIR_READ SYSMMU_ID_MASK(0xE, 0x1F)>,
			<9 TLB_CFG(BL1, PREFETCH_PREDICTION) DIR_READ SYSMMU_ID_MASK(0xF, 0x1F)>,
			<10 TLB_CFG(BL1, PREFETCH_PREDICTION) DIR_WRITE SYSMMU_ID_MASK(0x0, 0x1F)>,
			<11 TLB_CFG(BL1, PREFETCH_PREDICTION) DIR_WRITE SYSMMU_ID_MASK(0x1, 0x1F)>;
		port-name = "DPUF1 D1";
		power-domains = <&pd_dpuf1>;
	};

	sysmmu_d_drcp: sysmmu@0x17490000 {
		compatible = "samsung,sysmmu-v8";
		reg = <0 0x17490000 0x9000>;
		interrupts = <0 INTREQ__SYSMMU_D_DRCP_S1_NS IRQ_TYPE_LEVEL_HIGH>,
				<0 INTREQ__SYSMMU_D_DRCP_S1_S IRQ_TYPE_LEVEL_HIGH>;
		sysmmu,secure-irq;
		sysmmu,secure_base = <0x17480000>;
		qos = <15>;
		#iommu-cells = <0>;
		sysmmu,default_tlb = <TLB_CFG(BL1, PREFETCH_PREDICTION)>;
		sysmmu,tlb_property =
			<1 TLB_CFG(BL1, PREFETCH_PREDICTION) DIR_WRITE SYSMMU_ID_MASK(0x0, 0xF)>,
			<2 TLB_CFG(BL1, PREFETCH_PREDICTION) DIR_READ SYSMMU_ID_MASK(0x1, 0xF)>,
			<3 TLB_CFG(BL1, PREFETCH_PREDICTION) DIR_WRITE SYSMMU_ID_MASK(0x1, 0xF)>,
			<4 TLB_CFG(BL1, PREFETCH_PREDICTION) DIR_READ SYSMMU_ID_MASK(0x2, 0xF)>,
			<5 TLB_CFG(BL1, PREFETCH_NONE) DIR_READ SYSMMU_ID_MASK(0x3, 0xF)>,
			<6 TLB_CFG(BL2, PREFETCH_PREDICTION) DIR_READ SYSMMU_ID_MASK(0x4, 0xF)>;
		port-name = "DRCP (M0), DRCP (M1), DRCP (...";
		power-domains = <&pd_drcp>;
	};

	sysmmu_d_lme: sysmmu@0x177A0000 {
		compatible = "samsung,sysmmu-v8";
		reg = <0 0x177A0000 0x9000>;
		interrupts = <0 INTREQ__SYSMMU_D_LME_S1_NONSECURE IRQ_TYPE_LEVEL_HIGH>,
				<0 INTREQ__SYSMMU_D_LME_S1_SECURE IRQ_TYPE_LEVEL_HIGH>;
		sysmmu,secure-irq;
		sysmmu,secure_base = <0x177B0000>;
		qos = <15>;
		#iommu-cells = <0>;
		sysmmu,default_tlb = <TLB_CFG(BL16, PREFETCH_PREDICTION)>;
		sysmmu,tlb_property =
			<10 TLB_CFG(BL4, PREFETCH_NONE) DIR_WRITE SYSMMU_ID_MASK(0x3, 0x1F)>,
			<4 TLB_CFG(BL8, PREFETCH_PREDICTION) DIR_READ SYSMMU_ID_MASK(0xB, 0x1F)>,
			<9 TLB_CFG(BL4, PREFETCH_PREDICTION) DIR_READ SYSMMU_ID_MASK(0x13, 0x1F)>,
			<5 TLB_CFG(BL8, PREFETCH_PREDICTION) DIR_WRITE SYSMMU_ID_MASK(0xB, 0x1F)>,
			<19 TLB_CFG(BL1, PREFETCH_NONE) DIR_WRITE SYSMMU_ID_MASK(0x4, 0xF)>,
			<1 TLB_CFG(BL8, PREFETCH_PREDICTION) DIR_READ SYSMMU_ID_MASK(0x0, 0x3F)>,
			<6 TLB_CFG(BL4, PREFETCH_PREDICTION) DIR_READ SYSMMU_ID_MASK(0x8, 0x3F)>,
			<2 TLB_CFG(BL8, PREFETCH_PREDICTION) DIR_READ SYSMMU_ID_MASK(0x10, 0x3F)>,
			<7 TLB_CFG(BL4, PREFETCH_PREDICTION) DIR_READ SYSMMU_ID_MASK(0x18, 0x3F)>,
			<3 TLB_CFG(BL8, PREFETCH_PREDICTION) DIR_READ SYSMMU_ID_MASK(0x20, 0x3F)>,
			<13 TLB_CFG(BL1, PREFETCH_PREDICTION) DIR_READ SYSMMU_ID_MASK(0x28, 0x3F)>,
			<8 TLB_CFG(BL4, PREFETCH_PREDICTION) DIR_WRITE SYSMMU_ID_MASK(0x0, 0x1F)>,
			<11 TLB_CFG(BL2, PREFETCH_PREDICTION) DIR_WRITE SYSMMU_ID_MASK(0x8, 0x1F)>,
			<14 TLB_CFG(BL1, PREFETCH_PREDICTION) DIR_WRITE SYSMMU_ID_MASK(0x10, 0x1F)>,
			<15 TLB_CFG(BL1, PREFETCH_PREDICTION) DIR_WRITE SYSMMU_ID_MASK(0x18, 0x1F)>,
			<16 TLB_CFG(BL1, PREFETCH_PREDICTION) DIR_WRITE SYSMMU_ID_MASK(0x1, 0x1F)>,
			<17 TLB_CFG(BL1, PREFETCH_PREDICTION) DIR_WRITE SYSMMU_ID_MASK(0x9, 0x1F)>,
			<12 TLB_CFG(BL2, PREFETCH_NONE) DIR_READ SYSMMU_ID_MASK(0x1, 0x1F)>,
			<18 TLB_CFG(BL1, PREFETCH_NONE) DIR_WRITE SYSMMU_ID_MASK(0x2, 0xF)>;
		port-name = "ORBMCH, FRC_MC, LME";
		power-domains = <&pd_lme>;
	};

	sysmmu_d_m2m: sysmmu@0x18A00000 {
		compatible = "samsung,sysmmu-v8";
		reg = <0 0x18A00000 0x9000>;
		interrupts = <0 INTREQ__M2M__SYSMMU_D_M2M_PM_S1_NS IRQ_TYPE_LEVEL_HIGH>,
				<0 INTREQ__M2M__SYSMMU_D_M2M_PM_S1_S IRQ_TYPE_LEVEL_HIGH>;
		sysmmu,secure-irq;
		sysmmu,secure_base = <0x18A10000>;
		qos = <15>;
		#iommu-cells = <0>;
		sysmmu,default_tlb = <TLB_CFG(BL32, PREFETCH_NONE)>;
		sysmmu,tlb_property =
			<4 TLB_CFG(BL1, PREFETCH_PREDICTION) DIR_READ SYSMMU_ID_MASK(0xA, 0xF)>,
			<5 TLB_CFG(BL1, PREFETCH_PREDICTION) DIR_WRITE SYSMMU_ID_MASK(0x22, 0x3F)>,
			<6 TLB_CFG(BL1, PREFETCH_PREDICTION) DIR_WRITE SYSMMU_ID_MASK(0x32, 0x3F)>,
			<8 TLB_CFG(BL1, PREFETCH_NONE) DIR_WRITE SYSMMU_ID_MASK(0xA, 0xF)>,
			<1 TLB_CFG(BL8, PREFETCH_NONE) DIR_RW SYSMMU_ID_MASK(0x0, 0x7)>,
			<2 TLB_CFG(BL8, PREFETCH_NONE) DIR_RW SYSMMU_ID_MASK(0x1, 0x7)>,
			<7 TLB_CFG(BL2, PREFETCH_NONE) DIR_RW SYSMMU_ID_MASK(0x3, 0x7)>,
			<3 TLB_CFG(BL8, PREFETCH_NONE) DIR_RW SYSMMU_ID_MASK(0x4, 0x7)>;
		port-name = "M2M, JPEG0, JPEG1, ASTC, JSQZ";
		power-domains = <&pd_m2m>;
	};

	sysmmu_d0_mcfp: sysmmu@0x179A0000 {
		compatible = "samsung,sysmmu-v8";
		reg = <0 0x179A0000 0x9000>;
		interrupts = <0 INTREQ__SYSMMU_D0_MCFP_S1_NONSECURE IRQ_TYPE_LEVEL_HIGH>,
				<0 INTREQ__SYSMMU_D0_MCFP_S1_SECURE IRQ_TYPE_LEVEL_HIGH>;
		sysmmu,secure-irq;
		sysmmu,secure_base = <0x179B0000>;
		qos = <15>;
		#iommu-cells = <0>;
		sysmmu,default_tlb = <TLB_CFG(BL32, PREFETCH_PREDICTION)>;
		sysmmu,tlb_property =
			<1 TLB_CFG(BL1, PREFETCH_PREDICTION) DIR_READ SYSMMU_ID_MASK(0x1, 0x1)>,
			<2 TLB_CFG(BL1, PREFETCH_PREDICTION) DIR_WRITE SYSMMU_ID_MASK(0x0, 0x1)>,
			<3 TLB_CFG(BL1, PREFETCH_PREDICTION) DIR_WRITE SYSMMU_ID_MASK(0x1, 0x1)>;
		port-name = "MCFPV10.0 (M10)";
		power-domains = <&pd_mcfp>;
	};

	sysmmu_d1_mcfp: sysmmu@0x179D0000 {
		compatible = "samsung,sysmmu-v8";
		reg = <0 0x179D0000 0x9000>;
		interrupts = <0 INTREQ__SYSMMU_D1_MCFP_S1_NONSECURE IRQ_TYPE_LEVEL_HIGH>,
				<0 INTREQ__SYSMMU_D1_MCFP_S1_SECURE IRQ_TYPE_LEVEL_HIGH>;
		sysmmu,secure-irq;
		sysmmu,secure_base = <0x179E0000>;
		qos = <15>;
		#iommu-cells = <0>;
		sysmmu,default_tlb = <TLB_CFG(BL32, PREFETCH_PREDICTION)>;
		sysmmu,tlb_property =
			<1 TLB_CFG(BL1, PREFETCH_PREDICTION) DIR_READ SYSMMU_ID_MASK(0x1, 0x1)>,
			<2 TLB_CFG(BL1, PREFETCH_PREDICTION) DIR_WRITE SYSMMU_ID_MASK(0x0, 0x1)>,
			<3 TLB_CFG(BL1, PREFETCH_PREDICTION) DIR_WRITE SYSMMU_ID_MASK(0x1, 0x1)>;
		port-name = "MCFPV10.0 (M11)";
		power-domains = <&pd_mcfp>;
	};

	sysmmu_d2_mcfp: sysmmu@0x17A00000 {
		compatible = "samsung,sysmmu-v8";
		reg = <0 0x17A00000 0x9000>;
		interrupts = <0 INTREQ__SYSMMU_D2_MCFP_S1_NONSECURE IRQ_TYPE_LEVEL_HIGH>,
				<0 INTREQ__SYSMMU_D2_MCFP_S1_SECURE IRQ_TYPE_LEVEL_HIGH>;
		sysmmu,secure-irq;
		sysmmu,secure_base = <0x17A10000>;
		qos = <15>;
		#iommu-cells = <0>;
		sysmmu,default_tlb = <TLB_CFG(BL32, PREFETCH_PREDICTION)>;
		sysmmu,tlb_property =
			<1 TLB_CFG(BL1, PREFETCH_PREDICTION) DIR_READ SYSMMU_ID_MASK(0x1, 0x1)>,
			<2 TLB_CFG(BL1, PREFETCH_PREDICTION) DIR_WRITE SYSMMU_ID_MASK(0x0, 0x1)>;
		port-name = "MCFPV10.0 (M12)";
		power-domains = <&pd_mcfp>;
	};

	sysmmu_d3_mcfp: sysmmu@0x17A30000 {
		compatible = "samsung,sysmmu-v8";
		reg = <0 0x17A30000 0x9000>;
		interrupts = <0 INTREQ__SYSMMU_D3_MCFP_S1_NONSECURE IRQ_TYPE_LEVEL_HIGH>,
				<0 INTREQ__SYSMMU_D3_MCFP_S1_SECURE IRQ_TYPE_LEVEL_HIGH>;
		sysmmu,secure-irq;
		sysmmu,secure_base = <0x17A40000>;
		qos = <15>;
		#iommu-cells = <0>;
		sysmmu,default_tlb = <TLB_CFG(BL32, PREFETCH_PREDICTION)>;
		sysmmu,tlb_property =
			<1 TLB_CFG(BL1, PREFETCH_PREDICTION) DIR_READ SYSMMU_ID_MASK(0x1, 0x1)>;
		port-name = "MCFPV10.0 (M13), MCFPV10.0 (...";
		power-domains = <&pd_mcfp>;
	};

	sysmmu_d4_mcfp: sysmmu@0x17A60000 {
		compatible = "samsung,sysmmu-v8";
		reg = <0 0x17A60000 0x9000>;
		interrupts = <0 INTREQ__SYSMMU_D4_MCFP_S1_NONSECURE IRQ_TYPE_LEVEL_HIGH>,
				<0 INTREQ__SYSMMU_D4_MCFP_S1_SECURE IRQ_TYPE_LEVEL_HIGH>;
		sysmmu,secure-irq;
		sysmmu,secure_base = <0x17A70000>;
		qos = <15>;
		#iommu-cells = <0>;
		sysmmu,default_tlb = <TLB_CFG(BL1, PREFETCH_PREDICTION)>;
		sysmmu,tlb_property =
			<8 TLB_CFG(BL1, PREFETCH_NONE) DIR_READ SYSMMU_ID_MASK(0x2, 0xF)>,
			<2 TLB_CFG(BL1, PREFETCH_PREDICTION) DIR_READ SYSMMU_ID_MASK(0x3, 0xF)>,
			<3 TLB_CFG(BL1, PREFETCH_PREDICTION) DIR_READ SYSMMU_ID_MASK(0x4, 0xF)>,
			<4 TLB_CFG(BL1, PREFETCH_PREDICTION) DIR_READ SYSMMU_ID_MASK(0x5, 0xF)>,
			<5 TLB_CFG(BL1, PREFETCH_PREDICTION) DIR_READ SYSMMU_ID_MASK(0x6, 0xF)>,
			<6 TLB_CFG(BL1, PREFETCH_PREDICTION) DIR_READ SYSMMU_ID_MASK(0x7, 0xF)>,
			<7 TLB_CFG(BL1, PREFETCH_PREDICTION) DIR_READ SYSMMU_ID_MASK(0x8, 0xF)>;
		port-name = "MCFPV10.0 (M0), MCFPV10.0 (M...";
		power-domains = <&pd_mcfp>;
	};

	sysmmu_d5_mcfp: sysmmu@0x17A90000 {
		compatible = "samsung,sysmmu-v8";
		reg = <0 0x17A90000 0x9000>;
		interrupts = <0 INTREQ__SYSMMU_D5_MCFP_S1_NONSECURE IRQ_TYPE_LEVEL_HIGH>,
				<0 INTREQ__SYSMMU_D5_MCFP_S1_SECURE IRQ_TYPE_LEVEL_HIGH>;
		sysmmu,secure-irq;
		sysmmu,secure_base = <0x17AA0000>;
		qos = <15>;
		#iommu-cells = <0>;
		sysmmu,default_tlb = <TLB_CFG(BL1, PREFETCH_PREDICTION)>;
		sysmmu,tlb_property =
			<1 TLB_CFG(BL1, PREFETCH_PREDICTION) DIR_READ SYSMMU_ID_MASK(0x1, 0x1)>;
		port-name = "MCFPV10.0 (M1), MCFPV10.0 (M8)";
		power-domains = <&pd_mcfp>;
	};

	sysmmu_d0_mcsc: sysmmu@0x15C70000 {
		compatible = "samsung,sysmmu-v8";
		reg = <0 0x15C70000 0x9000>;
		interrupts = <0 INTREQ__SYSMMU_D0_MCSC_S1_NS IRQ_TYPE_LEVEL_HIGH>,
				<0 INTREQ__SYSMMU_D0_MCSC_S1_S IRQ_TYPE_LEVEL_HIGH>;
		sysmmu,secure-irq;
		sysmmu,secure_base = <0x15C80000>;
		qos = <15>;
		#iommu-cells = <0>;
		sysmmu,default_tlb = <TLB_CFG(BL32, PREFETCH_PREDICTION)>;
		sysmmu,tlb_property =
			<4 TLB_CFG(BL1, PREFETCH_PREDICTION) DIR_READ SYSMMU_ID_MASK(0x8, 0x1F)>,
			<2 TLB_CFG(BL16, PREFETCH_PREDICTION) DIR_WRITE SYSMMU_ID_MASK(0x0, 0x1F)>,
			<5 TLB_CFG(BL1, PREFETCH_PREDICTION) DIR_WRITE SYSMMU_ID_MASK(0x8, 0x1F)>,
			<3 TLB_CFG(BL16, PREFETCH_PREDICTION) DIR_WRITE SYSMMU_ID_MASK(0x10, 0x1F)>,
			<6 TLB_CFG(BL1, PREFETCH_PREDICTION) DIR_WRITE SYSMMU_ID_MASK(0x18, 0x1F)>,
			<1 TLB_CFG(BL32, PREFETCH_PREDICTION) DIR_READ SYSMMU_ID_MASK(0x1, 0xF)>,
			<7 TLB_CFG(BL1, PREFETCH_PREDICTION) DIR_READ SYSMMU_ID_MASK(0x9, 0xF)>,
			<9 TLB_CFG(BL1, PREFETCH_NONE) DIR_WRITE SYSMMU_ID_MASK(0x2, 0xF)>,
			<10 TLB_CFG(BL1, PREFETCH_NONE) DIR_WRITE SYSMMU_ID_MASK(0x3, 0xF)>,
			<8 TLB_CFG(BL1, PREFETCH_NONE) DIR_READ SYSMMU_ID_MASK(0x4, 0xF)>;
		port-name = "GDC_V10.0 (M0), GDC_V10.0 (M...";
		power-domains = <&pd_mcsc>;
	};

	sysmmu_d1_mcsc: sysmmu@0x15CA0000 {
		compatible = "samsung,sysmmu-v8";
		reg = <0 0x15CA0000 0x9000>;
		interrupts = <0 INTREQ__SYSMMU_D1_MCSC_S1_NS IRQ_TYPE_LEVEL_HIGH>,
				<0 INTREQ__SYSMMU_D1_MCSC_S1_S IRQ_TYPE_LEVEL_HIGH>;
		sysmmu,secure-irq;
		sysmmu,secure_base = <0x15CB0000>;
		qos = <15>;
		#iommu-cells = <0>;
		sysmmu,default_tlb = <TLB_CFG(BL1, PREFETCH_PREDICTION)>;
		sysmmu,tlb_property =
			<1 TLB_CFG(BL1, PREFETCH_PREDICTION) DIR_WRITE SYSMMU_ID_MASK(0x4, 0xF)>,
			<2 TLB_CFG(BL1, PREFETCH_PREDICTION) DIR_WRITE SYSMMU_ID_MASK(0x8, 0xF)>,
			<3 TLB_CFG(BL1, PREFETCH_PREDICTION) DIR_WRITE SYSMMU_ID_MASK(0x1, 0xF)>,
			<4 TLB_CFG(BL1, PREFETCH_PREDICTION) DIR_WRITE SYSMMU_ID_MASK(0x5, 0xF)>,
			<5 TLB_CFG(BL1, PREFETCH_PREDICTION) DIR_WRITE SYSMMU_ID_MASK(0x9, 0xF)>;
		port-name = "MCSCV10.0 (M3), MCSCV10.0 (M4)";
		power-domains = <&pd_mcsc>;
	};

	sysmmu_d2_mcsc: sysmmu@0x15CD0000 {
		compatible = "samsung,sysmmu-v8";
		reg = <0 0x15CD0000 0x9000>;
		interrupts = <0 INTREQ__SYSMMU_D2_MCSC_S1_NS IRQ_TYPE_LEVEL_HIGH>,
				<0 INTREQ__SYSMMU_D2_MCSC_S1_S IRQ_TYPE_LEVEL_HIGH>;
		sysmmu,secure-irq;
		sysmmu,secure_base = <0x15CE0000>;
		qos = <15>;
		#iommu-cells = <0>;
		sysmmu,default_tlb = <TLB_CFG(BL1, PREFETCH_PREDICTION)>;
		sysmmu,tlb_property =
			<1 TLB_CFG(BL1, PREFETCH_PREDICTION) DIR_READ SYSMMU_ID_MASK(0x8, 0x3F)>,
			<2 TLB_CFG(BL1, PREFETCH_PREDICTION) DIR_WRITE SYSMMU_ID_MASK(0x0, 0x3F)>,
			<3 TLB_CFG(BL1, PREFETCH_PREDICTION) DIR_WRITE SYSMMU_ID_MASK(0x8, 0x3F)>,
			<4 TLB_CFG(BL1, PREFETCH_PREDICTION) DIR_WRITE SYSMMU_ID_MASK(0x10, 0x3F)>,
			<5 TLB_CFG(BL1, PREFETCH_PREDICTION) DIR_WRITE SYSMMU_ID_MASK(0x18, 0x3F)>,
			<6 TLB_CFG(BL1, PREFETCH_PREDICTION) DIR_WRITE SYSMMU_ID_MASK(0x20, 0x3F)>,
			<15 TLB_CFG(BL1, PREFETCH_NONE) DIR_READ SYSMMU_ID_MASK(0x1, 0xF)>,
			<7 TLB_CFG(BL1, PREFETCH_PREDICTION) DIR_WRITE SYSMMU_ID_MASK(0x1, 0x3F)>,
			<8 TLB_CFG(BL1, PREFETCH_PREDICTION) DIR_WRITE SYSMMU_ID_MASK(0x9, 0x3F)>,
			<9 TLB_CFG(BL1, PREFETCH_PREDICTION) DIR_WRITE SYSMMU_ID_MASK(0x11, 0x3F)>,
			<10 TLB_CFG(BL1, PREFETCH_PREDICTION) DIR_WRITE SYSMMU_ID_MASK(0x19, 0x3F)>,
			<11 TLB_CFG(BL1, PREFETCH_PREDICTION) DIR_WRITE SYSMMU_ID_MASK(0x21, 0x3F)>,
			<12 TLB_CFG(BL1, PREFETCH_PREDICTION) DIR_WRITE SYSMMU_ID_MASK(0x2, 0x3F)>,
			<13 TLB_CFG(BL1, PREFETCH_PREDICTION) DIR_WRITE SYSMMU_ID_MASK(0x12, 0x3F)>,
			<14 TLB_CFG(BL1, PREFETCH_PREDICTION) DIR_WRITE SYSMMU_ID_MASK(0x22, 0x3F)>,
			<16 TLB_CFG(BL1, PREFETCH_NONE) DIR_WRITE SYSMMU_ID_MASK(0x3, 0xF)>,
			<17 TLB_CFG(BL1, PREFETCH_NONE) DIR_WRITE SYSMMU_ID_MASK(0x4, 0xF)>;
		port-name = "MCSCV10.0 (M0), MCSCV10.0 (M...";
		power-domains = <&pd_mcsc>;
	};

	sysmmu_d0_mfc0: sysmmu@0x18670000 {
		compatible = "samsung,sysmmu-v8";
		reg = <0 0x18670000 0x9000>;
		interrupts = <0 INTREQ__SYSMMU_MFC0D0_interrupt_s1_ns IRQ_TYPE_LEVEL_HIGH>,
				<0 INTREQ__SYSMMU_MFC0D0_interrupt_s1_s IRQ_TYPE_LEVEL_HIGH>;
		sysmmu,secure-irq;
		sysmmu,secure_base = <0x18680000>;
		qos = <15>;
		#iommu-cells = <0>;
		sysmmu,default_tlb = <TLB_CFG(BL8, PREFETCH_NONE)>;
		port-name = "FIMV_MFCM_V16.0 (M0)";
		power-domains = <&pd_mfc0>;
	};

	sysmmu_d1_mfc0: sysmmu@0x186A0000 {
		compatible = "samsung,sysmmu-v8";
		reg = <0 0x186A0000 0xA000>;
		interrupts = <0 INTREQ__SYSMMU_MFC0D1_interrupt_s1_ns IRQ_TYPE_LEVEL_HIGH>,
				<0 INTREQ__SYSMMU_MFC0D1_interrupt_s1_s IRQ_TYPE_LEVEL_HIGH>;
		sysmmu,secure-irq;
		sysmmu,secure_base = <0x186B0000>;
		qos = <15>;
		vmid_mask = <0x3>;
		#iommu-cells = <0>;
		sysmmu,default_tlb = <TLB_CFG(BL8, PREFETCH_NONE)>;
		sysmmu,tlb_property =
			<2 TLB_CFG(BL2, PREFETCH_NONE) DIR_WRITE SYSMMU_ID_MASK(0x1, 0x3)>,
			<1 TLB_CFG(BL1, PREFETCH_NONE) DIR_RW SYSMMU_ID_MASK(0x2, 0x3)>;
		port-name = "FIMV_MFCM_V16.0 (M1), FIMV_M...";
		power-domains = <&pd_mfc0>;
	};

	sysmmu_d0_mfc1: sysmmu@0x18870000 {
		compatible = "samsung,sysmmu-v8";
		reg = <0 0x18870000 0x9000>;
		interrupts = <0 INTREQ__SYSMMU_MFC1D0_interrupt_s1_ns IRQ_TYPE_LEVEL_HIGH>,
				<0 INTREQ__SYSMMU_MFC1D0_interrupt_s1_s IRQ_TYPE_LEVEL_HIGH>;
		sysmmu,secure-irq;
		sysmmu,secure_base = <0x18880000>;
		qos = <15>;
		#iommu-cells = <0>;
		sysmmu,default_tlb = <TLB_CFG(BL8, PREFETCH_NONE)>;
		port-name = "FIMV_MFCS_V16.0 (M0)";
		power-domains = <&pd_mfc1>;
	};

	sysmmu_d1_mfc1: sysmmu@0x188A0000 {
		compatible = "samsung,sysmmu-v8";
		reg = <0 0x188A0000 0x9000>;
		interrupts = <0 INTREQ__SYSMMU_MFC1D1_interrupt_s1_ns IRQ_TYPE_LEVEL_HIGH>,
				<0 INTREQ__SYSMMU_MFC1D1_interrupt_s1_s IRQ_TYPE_LEVEL_HIGH>;
		sysmmu,secure-irq;
		sysmmu,secure_base = <0x188B0000>;
		qos = <15>;
		#iommu-cells = <0>;
		sysmmu,default_tlb = <TLB_CFG(BL8, PREFETCH_NONE)>;
		port-name = "FIMV_MFCS_V16.0 (M1)";
		power-domains = <&pd_mfc1>;
	};

	sysmmu_d0_rgbp: sysmmu@0x17530000 {
		compatible = "samsung,sysmmu-v8";
		reg = <0 0x17530000 0x9000>;
		interrupts = <0 INTREQ__SYSMMU_D0_RGBP_S1_NS IRQ_TYPE_LEVEL_HIGH>,
				<0 INTREQ__SYSMMU_D0_RGBP_S1_S IRQ_TYPE_LEVEL_HIGH>;
		sysmmu,secure-irq;
		sysmmu,secure_base = <0x17540000>;
		qos = <15>;
		#iommu-cells = <0>;
		sysmmu,default_tlb = <TLB_CFG(BL1, PREFETCH_PREDICTION)>;
		sysmmu,tlb_property =
			<1 TLB_CFG(BL1, PREFETCH_PREDICTION) DIR_WRITE SYSMMU_ID_MASK(0x0, 0x7)>,
			<2 TLB_CFG(BL1, PREFETCH_PREDICTION) DIR_WRITE SYSMMU_ID_MASK(0x4, 0x7)>,
			<3 TLB_CFG(BL1, PREFETCH_PREDICTION) DIR_READ SYSMMU_ID_MASK(0x1, 0x7)>,
			<4 TLB_CFG(BL1, PREFETCH_PREDICTION) DIR_WRITE SYSMMU_ID_MASK(0x1, 0x7)>,
			<5 TLB_CFG(BL1, PREFETCH_PREDICTION) DIR_READ SYSMMU_ID_MASK(0x2, 0x7)>,
			<6 TLB_CFG(BL1, PREFETCH_PREDICTION) DIR_WRITE SYSMMU_ID_MASK(0x2, 0x7)>,
			<7 TLB_CFG(BL1, PREFETCH_NONE) DIR_READ SYSMMU_ID_MASK(0x3, 0x7)>;
		port-name = "RGBP (M0), RGBP (M0), RGBP (...";
		power-domains = <&pd_rgbp>;
	};

	sysmmu_d1_rgbp: sysmmu@0x17570000 {
		compatible = "samsung,sysmmu-v8";
		reg = <0 0x17570000 0x9000>;
		interrupts = <0 INTREQ__SYSMMU_D1_RGBP_S1_NS IRQ_TYPE_LEVEL_HIGH>,
				<0 INTREQ__SYSMMU_D1_RGBP_S1_S IRQ_TYPE_LEVEL_HIGH>;
		sysmmu,secure-irq;
		sysmmu,secure_base = <0x17580000>;
		qos = <15>;
		#iommu-cells = <0>;
		sysmmu,default_tlb = <TLB_CFG(BL1, PREFETCH_PREDICTION)>;
		sysmmu,tlb_property =
			<1 TLB_CFG(BL1, PREFETCH_PREDICTION) DIR_WRITE SYSMMU_ID_MASK(0x0, 0x7)>,
			<2 TLB_CFG(BL1, PREFETCH_PREDICTION) DIR_READ SYSMMU_ID_MASK(0x1, 0x7)>,
			<3 TLB_CFG(BL1, PREFETCH_PREDICTION) DIR_WRITE SYSMMU_ID_MASK(0x1, 0x7)>,
			<4 TLB_CFG(BL1, PREFETCH_NONE) DIR_WRITE SYSMMU_ID_MASK(0x2, 0x7)>,
			<5 TLB_CFG(BL1, PREFETCH_NONE) DIR_WRITE SYSMMU_ID_MASK(0x3, 0x7)>;
		port-name = "RGBP (M4), RGBP (M4), RGBP (...";
		power-domains = <&pd_rgbp>;
	};

	sysmmu_d_yuvp: sysmmu@0x18030000 {
		compatible = "samsung,sysmmu-v8";
		reg = <0 0x18030000 0x9000>;
		interrupts = <0 INTREQ__SYSMMU_D_YUVP_S1_NS IRQ_TYPE_LEVEL_HIGH>,
				<0 INTREQ__SYSMMU_D_YUVP_S1_S IRQ_TYPE_LEVEL_HIGH>;
		sysmmu,secure-irq;
		sysmmu,secure_base = <0x18040000>;
		qos = <15>;
		#iommu-cells = <0>;
		sysmmu,default_tlb = <TLB_CFG(BL1, PREFETCH_PREDICTION)>;
		sysmmu,tlb_property =
			<1 TLB_CFG(BL1, PREFETCH_PREDICTION) DIR_READ SYSMMU_ID_MASK(0x1, 0xF)>,
			<2 TLB_CFG(BL1, PREFETCH_PREDICTION) DIR_READ SYSMMU_ID_MASK(0x2, 0xF)>,
			<3 TLB_CFG(BL1, PREFETCH_PREDICTION) DIR_READ SYSMMU_ID_MASK(0x3, 0xF)>,
			<4 TLB_CFG(BL1, PREFETCH_NONE) DIR_READ SYSMMU_ID_MASK(0x4, 0xF)>;
		port-name = "YUVP (M0), YUVP (M1), YUVP (...";
		power-domains = <&pd_yuvp>;
	};
};
